VERSION ""

NS_ :

BS_:

BU_: VCU SOBEK_SDCxxxx RS_RPS BypassValve OilPump SOBEK_SDCxxxx WaterPump

BO_ 865 SOBEK_SetSpeed: 2 VCU
 SG_ SOBEK_SpeedCommand : 0|16@1+ (1,0) [0|0] "rpm"  SOBEK_SDCxxxx

BO_ 881 SOBEK_Status: 8 SOBEK_SDCxxxx
 SG_ SOBEK_TempFeedback : 32|16@1+ (0.1,0) [0|0] "100m°C"  VCU
 SG_ SOBEK_DCVoltageFeedback : 48|16@1+ (1,0) [0|0] "mV"  VCU
 SG_ SOBEK_SpeedFeedback : 0|16@1- (1,0) [0|0] "rpm"  VCU
 SG_ SOBEK_CurrentFeedback : 16|16@1- (1,0) [0|0] "100mA"  VCU

BO_ 897 SOBEK_Diagnostic_Message: 5 SOBEK_SDCxxxx
 SG_ Diagnostic_header M : 0|8@1+ (1,0) [16|16] ""  VCU
 SG_ Master_ID m1 : 8|16@1+ (1,0) [0|0] ""  VCU
 SG_ Status_ID m2 : 24|16@1+ (1,0) [0|0] ""  VCU
 SG_ Command_ID m2 : 8|16@1+ (1,0) [0|0] ""  VCU
 SG_ GWS_Status_ID m3 : 24|16@1+ (1,0) [0|0] ""  VCU
 SG_ GWS_Command_ID m3 : 8|16@1+ (1,0) [0|0] ""  VCU
 SG_ UNTERNUMMER_SOFTWARE m4 : 8|8@1+ (1,0) [0|0] ""  VCU
 SG_ HAUPTNUMMER_SOFTWARE m4 : 16|8@1+ (1,0) [0|0] ""  VCU
 SG_ ParameterVersion m5 : 8|16@1+ (1,0) [0|0] ""  VCU
 SG_ Betriebszaehler m6 : 8|32@1+ (1,0) [0|0] ""  VCU
 SG_ Encoder_Offset m7 : 8|16@1+ (1,0) [0|0] ""  VCU
 SG_ Side_MOSFETs m16 : 8|2@1+ (1,0) [0|0] ""  VCU
 SG_ Offset_of_EMF_measurement m16 : 10|1@1+ (1,0) [0|0] ""  VCU
 SG_ Offset_of_current_measurement m16 : 11|1@1+ (1,0) [0|0] ""  VCU
 SG_ Under_voltage_Selftest m16 : 12|1@1+ (1,0) [0|0] ""  VCU
 SG_ Over_voltage_Selftest m16 : 13|1@1+ (1,0) [0|0] ""  VCU
 SG_ Over_temperature_of_MOSFETs m16 : 14|1@1+ (1,0) [0|0] ""  VCU
 SG_ Disconnection_of_motor_cables m16 : 15|1@1+ (1,0) [0|0] ""  VCU
 SG_ No_parameter_data_in_EEPROM m16 : 16|1@1+ (1,0) [0|0] ""  VCU
 SG_ CRC_error_of_EEPROM m16 : 17|1@1+ (1,0) [0|0] ""  VCU
 SG_ Size_of_EEPROM m16 : 18|1@1+ (1,0) [0|0] ""  VCU
 SG_ Version_of_EEPROM m16 : 19|1@1+ (1,0) [0|0] ""  VCU
 SG_ Not_defined m16 : 20|1@1+ (1,0) [0|0] ""  VCU
 SG_ Not_defined m16 : 21|1@1+ (1,0) [0|0] ""  VCU
 SG_ Not_defined m16 : 22|1@1+ (1,0) [0|0] ""  VCU
 SG_ Not_defined m16 : 23|1@1+ (1,0) [0|0] ""  VCU
 SG_ Over_voltage_Operation m16 : 24|1@1+ (1,0) [0|0] ""  VCU
 SG_ Over_voltage m16 : 25|1@1+ (1,0) [0|0] ""  VCU
 SG_ Under_voltage_Operation m16 : 26|1@1+ (1,0) [0|0] ""  VCU
 SG_ Over_temperature m16 : 27|1@1+ (1,0) [0|0] ""  VCU
 SG_ Operation_system_watchdog m16 : 28|1@1+ (1,0) [0|0] ""  VCU
 SG_ Not_defined m16 : 29|1@1+ (1,0) [0|0] ""  VCU
 SG_ Not_defined m16 : 30|1@1+ (1,0) [0|0] ""  VCU

BO_ 260 Tool_RealTimeClock_Cmd: 6 VCU
 SG_ RPS_RTC_Second : 40|8@1- (1,0) [0|59] "" Vector__XXX
 SG_ RPS_RTC_Minute : 32|8@1- (1,0) [0|59] "" Vector__XXX
 SG_ RPS_RTC_Hour : 24|8@1- (1,0) [0|23] "" Vector__XXX
 SG_ RPS_RTC_Day : 16|8@1- (1,0) [0|31] "" Vector__XXX
 SG_ RPS_RTC_Month : 8|8@1- (1,0) [0|12] "" Vector__XXX
 SG_ RPS_RTC_Year : 0|8@1- (1,0) [0|255] "" Vector__XXX

BO_ 259 RPS_RealTimeClock_Data: 6 RS_RPS
 SG_ RPS_RTC_Second : 40|8@1- (1,0) [0|59] "" Vector__XXX
 SG_ RPS_RTC_Minute : 32|8@1- (1,0) [0|59] "" Vector__XXX
 SG_ RPS_RTC_Hour : 24|8@1- (1,0) [0|23] "" Vector__XXX
 SG_ RPS_RTC_Day : 16|8@1- (1,0) [0|31] "" Vector__XXX
 SG_ RPS_RTC_Month : 8|8@1- (1,0) [0|12] "" Vector__XXX
 SG_ RPS_RTC_Year : 0|8@1- (1,0) [0|255] "" Vector__XXX

BO_ 289 RPS_BMS_ASICStateInfo: 8 RS_RPS
 SG_ RPS_NBMSASICBalanceCond : 31|8@0+ (1,0) [0|255] "" Vector__XXX
 SG_ RPS_NBMSASICPowerOffCnt : 39|8@0+ (1,0) [0|255] "" Vector__XXX
 SG_ RPS_NBMSASICFirstResetType : 15|8@0+ (1,0) [0|255] "" Vector__XXX
 SG_ RPS_NBMSASICResetCount : 7|8@0+ (1,0) [0|255] "" Vector__XXX
 SG_ RPS_NBMSASICState : 23|8@0+ (1,0) [0|255] "" Vector__XXX
 SG_ RPS_NBMSASICBalanceMask : 55|16@0+ (1,0) [0|66535] "" Vector__XXX

BO_ 258 RPS_Programming_Command: 8 Vector__XXX

BO_ 257 RPS_Programming_Response: 8 Vector__XXX

BO_ 276 RPS_OutputStates4: 8 RS_RPS
 SG_ RPS_BBalancingActive : 20|1@0+ (1,0) [0|1] "" Vector__XXX
 SG_ RPS_BPackOverloadWarning : 19|1@0+ (1,0) [0|1] "" Vector__XXX
 SG_ RPS_VOutput : 39|8@0+ (0.08,0) [0|20.4] "V" Vector__XXX
 SG_ RPS_VBattery : 47|8@0+ (0.08,0) [0|20.4] "V" Vector__XXX
 SG_ RPS_NRPSLatestFault : 31|8@0+ (1,0) [0|255] "" Vector__XXX
 SG_ RPS_NBMSControlState : 23|3@0+ (1,0) [0|5] "" Vector__XXX
 SG_ RPS_IBattery : 55|16@0- (0.01,0) [-327.68|327.67] "A" Vector__XXX
 SG_ RPS_BPrimaryOutoutEnableState : 17|1@0+ (1,0) [0|1] "" Vector__XXX
 SG_ RPS_BPackHealthState : 18|1@0+ (1,0) [0|1] "" Vector__XXX
 SG_ RPS_BMasterEnableInputState : 16|1@0+ (1,0) [0|1] "" Vector__XXX
 SG_ RPS_IOutput26 : 15|8@0+ (0.01,0) [0|2.55] "A" Vector__XXX
 SG_ RPS_IOutput25 : 7|8@0+ (0.01,0) [0|2.55] "A" Vector__XXX

BO_ 275 RPS_OutputStates3: 8 RS_RPS
 SG_ RPS_IOutput24 : 63|8@0+ (0.01,0) [0|2.55] "A" Vector__XXX
 SG_ RPS_IOutput23 : 55|8@0+ (0.01,0) [0|2.55] "A" Vector__XXX
 SG_ RPS_IOutput22 : 47|8@0+ (0.01,0) [0|2.55] "A" Vector__XXX
 SG_ RPS_IOutput21 : 39|8@0+ (0.01,0) [0|2.55] "A" Vector__XXX
 SG_ RPS_IOutput20 : 31|8@0+ (0.01,0) [0|2.55] "A" Vector__XXX
 SG_ RPS_IOutput19 : 23|8@0+ (0.01,0) [0|2.55] "A" Vector__XXX
 SG_ RPS_IOutput18 : 15|8@0+ (0.01,0) [0|2.55] "A" Vector__XXX
 SG_ RPS_IOutput17 : 7|8@0+ (0.01,0) [0|2.55] "A" Vector__XXX

BO_ 274 RPS_OutputStates2: 8 RS_RPS
 SG_ RPS_IOutput9 : 7|8@0+ (0.04,0) [0|10.2] "A" Vector__XXX
 SG_ RPS_IOutput12 : 31|8@0+ (0.04,0) [0|10.2] "A" Vector__XXX
 SG_ RPS_IOutput16 : 63|8@0+ (0.04,0) [0|10.2] "A" Vector__XXX
 SG_ RPS_IOutput15 : 55|8@0+ (0.04,0) [0|10.2] "A" Vector__XXX
 SG_ RPS_IOutput14 : 47|8@0+ (0.04,0) [0|10.2] "A" Vector__XXX
 SG_ RPS_IOutput13 : 39|8@0+ (0.04,0) [0|10.2] "A" Vector__XXX
 SG_ RPS_IOutput11 : 23|8@0+ (0.04,0) [0|10.2] "A" Vector__XXX
 SG_ RPS_IOutput10 : 15|8@0+ (0.04,0) [0|10.2] "A" Vector__XXX

BO_ 273 RPS_OutputStates1: 8 RS_RPS
 SG_ RPS_IOutput8 : 63|8@0+ (0.08,0) [0|20.4] "A" Vector__XXX
 SG_ RPS_IOutput7 : 55|8@0+ (0.08,0) [0|20.4] "A" Vector__XXX
 SG_ RPS_IOutput6 : 47|8@0+ (0.08,0) [0|20.4] "A" Vector__XXX
 SG_ RPS_IOutput5 : 39|8@0+ (0.08,0) [0|20.4] "A" Vector__XXX
 SG_ RPS_IOutput4 : 31|8@0+ (0.08,0) [0|20.4] "A" Vector__XXX
 SG_ RPS_IOutput3 : 23|8@0+ (0.08,0) [0|20.4] "A" Vector__XXX
 SG_ RPS_IOutput2 : 15|8@0+ (0.08,0) [0|20.4] "A" Vector__XXX
 SG_ RPS_IOutput1 : 7|8@0+ (0.08,0) [0|20.4] "A" Vector__XXX

BO_ 272 RPS_OutputStates0: 8 RS_RPS
 SG_ RPS_BOutputResetState : 54|1@0+ (1,0) [0|1] "" Vector__XXX
 SG_ RPS_BIsolatorStateRequestFB : 53|1@0+ (1,0) [0|1] "" Vector__XXX
 SG_ RPS_BIsolatorOverrideActive : 52|1@0+ (1,0) [0|1] "" Vector__XXX
 SG_ RPS_NOutput9State : 17|2@0+ (1,0) [0|3] "" Vector__XXX
 SG_ RPS_NOutput8State : 15|2@0+ (1,0) [0|3] "" Vector__XXX
 SG_ RPS_NOutput7State : 13|2@0+ (1,0) [0|3] "" Vector__XXX
 SG_ RPS_NOutput6State : 11|2@0+ (1,0) [0|3] "" Vector__XXX
 SG_ RPS_NOutput5State : 9|2@0+ (1,0) [0|3] "" Vector__XXX
 SG_ RPS_NOutput4State : 7|2@0+ (1,0) [0|3] "" Vector__XXX
 SG_ RPS_NOutput3State : 5|2@0+ (1,0) [0|3] "" Vector__XXX
 SG_ RPS_NOutput2State : 3|2@0+ (1,0) [0|3] "" Vector__XXX
 SG_ RPS_NOutput26State : 51|2@0+ (1,0) [0|3] "" Vector__XXX
 SG_ RPS_NOutput25State : 49|2@0+ (1,0) [0|3] "" Vector__XXX
 SG_ RPS_NOutput24State : 47|2@0+ (1,0) [0|3] "" Vector__XXX
 SG_ RPS_NOutput23State : 45|2@0+ (1,0) [0|3] "" Vector__XXX
 SG_ RPS_NOutput22State : 43|2@0+ (1,0) [0|3] "" Vector__XXX
 SG_ RPS_NOutput21State : 41|2@0+ (1,0) [0|3] "" Vector__XXX
 SG_ RPS_NOutput20State : 39|2@0+ (1,0) [0|3] "" Vector__XXX
 SG_ RPS_NOutput1State : 1|2@0+ (1,0) [0|3] "" Vector__XXX
 SG_ RPS_NOutput19State : 37|2@0+ (1,0) [0|3] "" Vector__XXX
 SG_ RPS_NOutput18State : 35|2@0+ (1,0) [0|3] "" Vector__XXX
 SG_ RPS_NOutput17State : 33|2@0+ (1,0) [0|3] "" Vector__XXX
 SG_ RPS_NOutput16State : 31|2@0+ (1,0) [0|3] "" Vector__XXX
 SG_ RPS_NOutput15State : 29|2@0+ (1,0) [0|3] "" Vector__XXX
 SG_ RPS_NOutput14State : 27|2@0+ (1,0) [0|3] "" Vector__XXX
 SG_ RPS_NOutput13State : 25|2@0+ (1,0) [0|3] "" Vector__XXX
 SG_ RPS_NOutput12State : 23|2@0+ (1,0) [0|3] "" Vector__XXX
 SG_ RPS_NOutput11State : 21|2@0+ (1,0) [0|3] "" Vector__XXX
 SG_ RPS_NOutput10State : 19|2@0+ (1,0) [0|3] "" Vector__XXX

BO_ 256 RPS_OutputCommand: 8 VCU
 SG_ RPS_BIsolatorOverrideStateDem : 28|1@0+ (1,0) [0|0] "" Vector__XXX
 SG_ RPS_BIsolatorOverrideEnableDem : 27|1@0+ (1,0) [0|0] "" Vector__XXX
 SG_ RPS_BOutput23EnableDem : 22|1@0+ (1,0) [0|0] "" Vector__XXX
 SG_ RPS_BOutputResetDem : 26|1@0+ (1,0) [0|0] "" Vector__XXX
 SG_ RPS_BOutput9EnableDem : 8|1@0+ (1,0) [0|0] "" Vector__XXX
 SG_ RPS_BOutput8EnableDem : 7|1@0+ (1,0) [0|0] "" Vector__XXX
 SG_ RPS_BOutput7EnableDem : 6|1@0+ (1,0) [0|0] "" Vector__XXX
 SG_ RPS_BOutput6EnableDem : 5|1@0+ (1,0) [0|0] "" Vector__XXX
 SG_ RPS_BOutput5EnableDem : 4|1@0+ (1,0) [0|0] "" Vector__XXX
 SG_ RPS_BOutput4EnableDem : 3|1@0+ (1,0) [0|0] "" Vector__XXX
 SG_ RPS_BOutput3EnableDem : 2|1@0+ (1,0) [0|0] "" Vector__XXX
 SG_ RPS_BOutput2EnableDem : 1|1@0+ (1,0) [0|0] "" Vector__XXX
 SG_ RPS_BOutput26EnableDem : 25|1@0+ (1,0) [0|0] "" Vector__XXX
 SG_ RPS_BOutput25EnableDem : 24|1@0+ (1,0) [0|0] "" Vector__XXX
 SG_ RPS_BOutput24EnableDem : 23|1@0+ (1,0) [0|0] "" Vector__XXX
 SG_ RPS_BOutput22EnableDem : 21|1@0+ (1,0) [0|0] "" Vector__XXX
 SG_ RPS_BOutput21EnableDem : 20|1@0+ (1,0) [0|0] "" Vector__XXX
 SG_ RPS_BOutput20EnableDem : 19|1@0+ (1,0) [0|0] "" Vector__XXX
 SG_ RPS_BOutput1EnableDem : 0|1@0+ (1,0) [0|0] "" Vector__XXX
 SG_ RPS_BOutput19EnableDem : 18|1@0+ (1,0) [0|0] "" Vector__XXX
 SG_ RPS_BOutput18EnableDem : 17|1@0+ (1,0) [0|0] "" Vector__XXX
 SG_ RPS_BOutput17EnableDem : 16|1@0+ (1,0) [0|0] "" Vector__XXX
 SG_ RPS_BOutput16EnableDem : 15|1@0+ (1,0) [0|0] "" Vector__XXX
 SG_ RPS_BOutput15EnableDem : 14|1@0+ (1,0) [0|0] "" Vector__XXX
 SG_ RPS_BOutput14EnableDem : 13|1@0+ (1,0) [0|0] "" Vector__XXX
 SG_ RPS_BOutput13EnableDem : 12|1@0+ (1,0) [0|0] "" Vector__XXX
 SG_ RPS_BOutput12EnableDem : 11|1@0+ (1,0) [0|0] "" Vector__XXX
 SG_ RPS_BOutput11EnableDem : 10|1@0+ (1,0) [0|0] "" Vector__XXX
 SG_ RPS_BOutput10EnableDem : 9|1@0+ (1,0) [0|0] "" Vector__XXX

BO_ 305 RPS_Rotations: 8 RS_RPS
 SG_ RPS_nRotationZ : 39|16@0- (0.01,0) [-500|500] "°/s" Vector__XXX
 SG_ RPS_nRotationY : 23|16@0- (0.01,0) [-500|500] "°/s" Vector__XXX
 SG_ RPS_nRotationX : 7|16@0- (0.01,0) [-500|500] "°/s" Vector__XXX

BO_ 304 RPS_Accels: 8 RS_RPS
 SG_ RPS_gAccelZ : 39|16@0- (0.001,0) [-16|16] "g" Vector__XXX
 SG_ RPS_gAccelY : 23|16@0- (0.001,0) [-16|16] "g" Vector__XXX
 SG_ RPS_gAccelX : 7|16@0- (0.001,0) [-16|16] "g" Vector__XXX

BO_ 288 RPS_VersionInfo: 8 RS_RPS
 SG_ RPS_HWVersion_DMinor : 31|8@0+ (1,0) [0|255] "" Vector__XXX
 SG_ RPS_HWVersion_DMajor : 23|8@0+ (1,0) [0|255] "" Vector__XXX
 SG_ RPS_SWVersionIDMinor : 15|8@0+ (1,0) [0|255] "" Vector__XXX
 SG_ RPS_SWVersionIDMajor : 7|8@0+ (1,0) [0|255] "" Vector__XXX

BO_ 278 RPS_BatteryTemps: 8 RS_RPS
 SG_ RPS_TPack3 : 23|8@0+ (0.5,-20) [-20|105] "degC" Vector__XXX
 SG_ RPS_TPack2 : 15|8@0+ (0.5,-20) [-20|105] "degC" Vector__XXX
 SG_ RPS_TPack1 : 7|8@0+ (0.5,-20) [-20|105] "degC" Vector__XXX

BO_ 277 RPS_BatteryVoltages: 8 RS_RPS
 SG_ RPS_VCellStack4 : 55|16@0+ (0.0001,0) [0|6] "V" Vector__XXX
 SG_ RPS_VCellStack3 : 39|16@0+ (0.0001,0) [0|6] "V" Vector__XXX
 SG_ RPS_VCellStack2 : 23|16@0+ (0.0001,0) [0|6] "V" Vector__XXX
 SG_ RPS_VCellStack1 : 7|16@0+ (0.0001,0) [0|6] "V" Vector__XXX

BO_ 869 CommandMsg: 2 VCU
 SG_ PositionRef : 0|16@1+ (0.1,0) [0|1000] "%" Vector__XXX

BO_ 885 StatusMsg: 2 BypassValve
 SG_ Position : 0|16@1+ (0.1,0) [0|1000] "%" Vector__XXX

BO_ 837 DiagnosticMsg: 5 BypassValve
 SG_ DeviceID3 m9 : 8|32@1+ (1,0) [0|4294967295] "" Vector__XXX
 SG_ DeviceID2 m8 : 8|32@1+ (1,0) [0|4294967295] "" Vector__XXX
 SG_ DeviceID1 m7 : 8|32@1+ (1,0) [0|4294967295] "" Vector__XXX
 SG_ CommandID m3 : 8|16@1+ (1,0) [0|65535] "" Vector__XXX
 SG_ BootloaderVersion m6 : 8|16@1+ (1,0) [0|65535] "" Vector__XXX
 SG_ BootloaderUpdateCounter m6 : 24|16@1+ (1,0) [0|65535] "" Vector__XXX
 SG_ OperationError m16 : 8|16@1+ (1,0) [0|65535] "" Vector__XXX
 SG_ SelfcheckStatus m1 : 8|16@1+ (1,0) [0|65535] "" Vector__XXX
 SG_ DiagnosticHeader M : 0|8@1+ (1,0) [0|255] "" Vector__XXX
 SG_ MasterID m2 : 8|16@1+ (1,0) [0|65535] "" Vector__XXX
 SG_ StatusID m3 : 24|16@1+ (1,0) [0|0] "" Vector__XXX
 SG_ FirmwareVersion m4 : 8|16@1+ (1,0) [0|0] "" Vector__XXX
 SG_ ParameterVersion m4 : 24|16@1+ (1,0) [0|65535] "" Vector__XXX
 SG_ OperationCounter m5 : 8|32@1+ (1,0) [0|4294967295] "s" Vector__XXX

BO_ 1376 SOBEK_Master: 8 Vector__XXX

BO_ 1377 SOBEK_Command: 2 VCU
 SG_ Target_Speed : 0|16@1- (1,0) [-32768|32767] "rpm"  SOBEK_SDCxxxx

BO_ 1378 SOBEK_Status: 8 OilPump
 SG_ ESC_Temperature : 32|16@1+ (0.1,0) [0|200] "Celsius" Vector__XXX
 SG_ DC_Voltage : 48|16@1+ (0.001,0) [0|65.535] "V" Vector__XXX
 SG_ Motor_Speed : 0|16@1- (1,0) [-32768|32767] "rpm" Vector__XXX
 SG_ Motor_Current : 16|16@1+ (0.1,0) [0|6553.5] "A" Vector__XXX

BO_ 1379 SOBEK_Diagnostic: 5 OilPump
 SG_ HW_ID3 m9 : 8|32@1+ (1,0) [0|4294967295] "" Vector__XXX
 SG_ HW_ID2 m8 : 8|32@1+ (1,0) [0|4294967295] "" Vector__XXX
 SG_ HW_ID1 m7 : 8|32@1+ (1,0) [0|4294967295] "" Vector__XXX
 SG_ Operation_Warning m16 : 16|8@1+ (1,0) [0|255] "" Vector__XXX
 SG_ Bootloader_Version m6 : 8|16@1+ (1,0) [0|65535] "" Vector__XXX
 SG_ Bootloader_Update_Counter m6 : 24|16@1+ (1,0) [0|65535] "" Vector__XXX
 SG_ Operation_Error m16 : 8|8@1+ (1,0) [0|255] "" Vector__XXX
 SG_ Parameter_Version m4 : 24|16@1+ (1,0) [0|65535] "" Vector__XXX
 SG_ Self_Test m1 : 8|16@1+ (1,0) [0|65535] "" Vector__XXX
 SG_ Diagnostic_Header M : 0|8@1+ (1,0) [0|255] "" Vector__XXX
 SG_ Master_ID m2 : 8|11@1+ (1,0) [0|2047] "" Vector__XXX
 SG_ Status_ID m3 : 24|11@1+ (1,0) [0|2047] "" Vector__XXX
 SG_ Command_ID m3 : 8|11@1+ (1,0) [0|2047] "" Vector__XXX
 SG_ Software_Version m4 : 8|16@1+ (1,0) [0|65535] "" Vector__XXX
 SG_ Operation_Counter m5 : 8|32@1+ (1,0) [0|4294967295] "s" Vector__XXX

BO_ 1360 SOBEK_Master: 8 Vector__XXX

BO_ 1361 SOBEK_Command: 2 VCU
 SG_ Target_Speed : 0|16@1- (1,0) [-32768|32767] "rpm" Vector__XXX

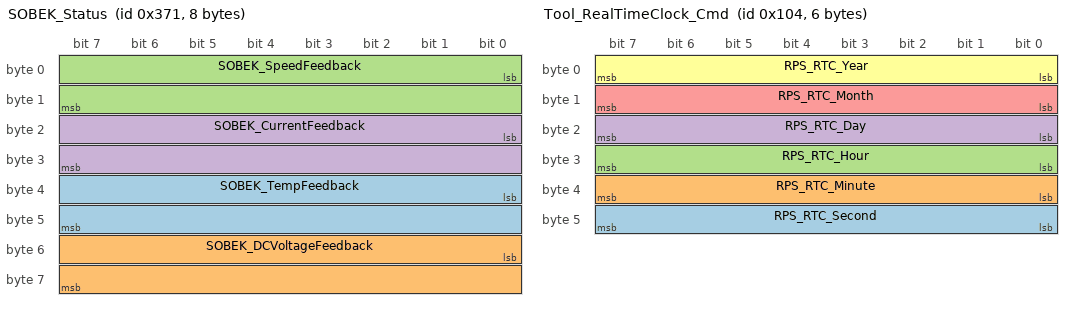
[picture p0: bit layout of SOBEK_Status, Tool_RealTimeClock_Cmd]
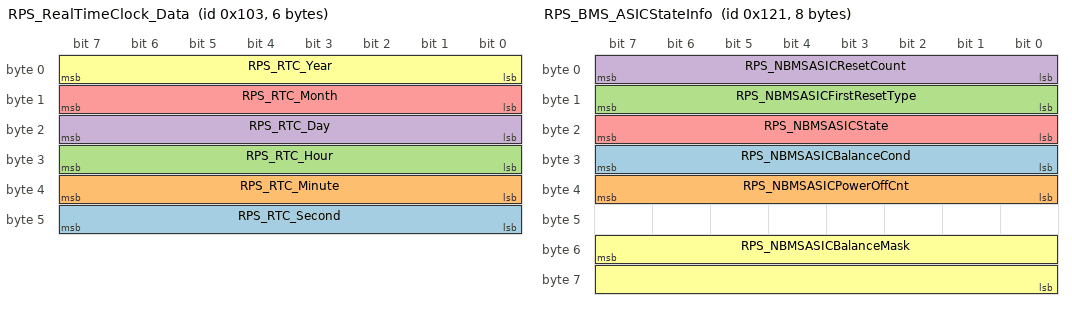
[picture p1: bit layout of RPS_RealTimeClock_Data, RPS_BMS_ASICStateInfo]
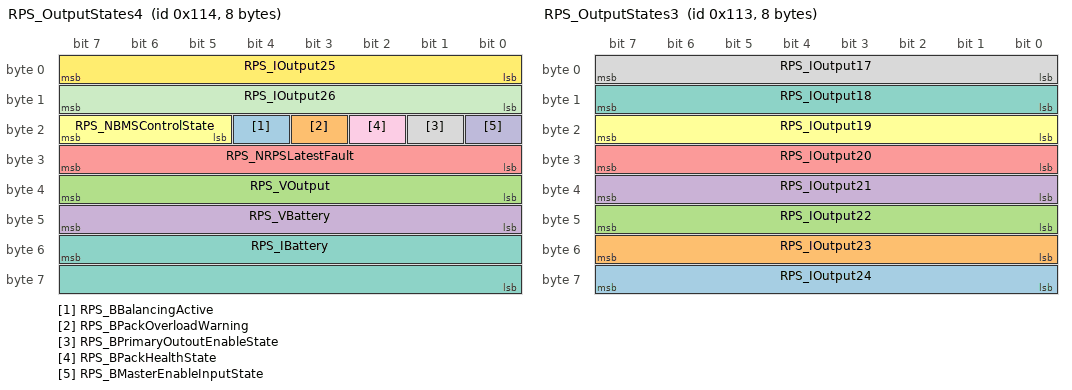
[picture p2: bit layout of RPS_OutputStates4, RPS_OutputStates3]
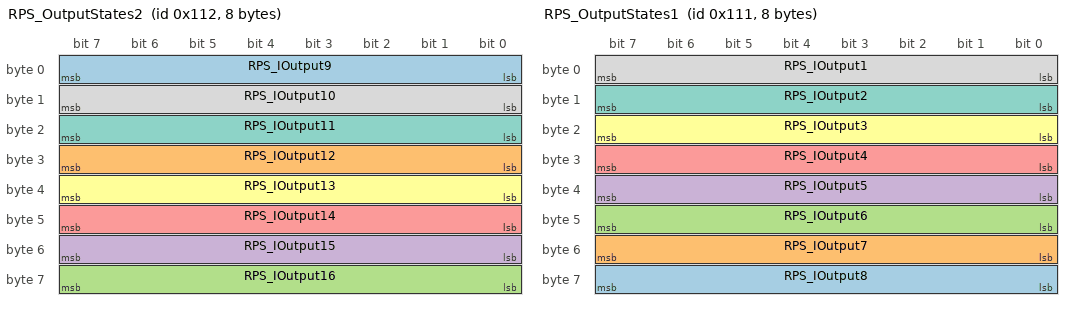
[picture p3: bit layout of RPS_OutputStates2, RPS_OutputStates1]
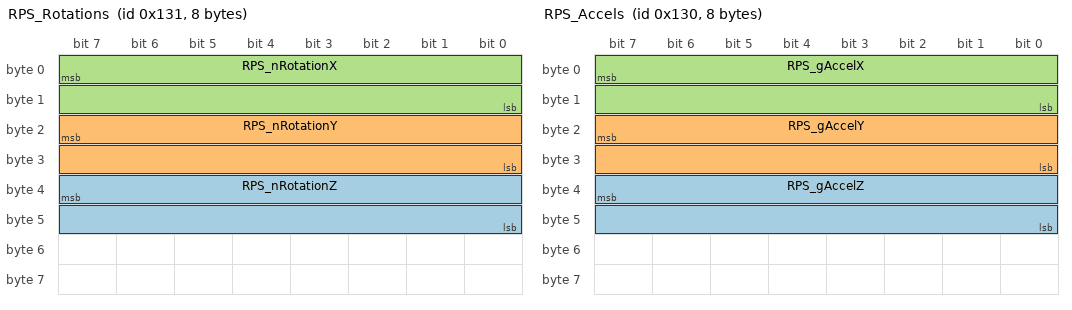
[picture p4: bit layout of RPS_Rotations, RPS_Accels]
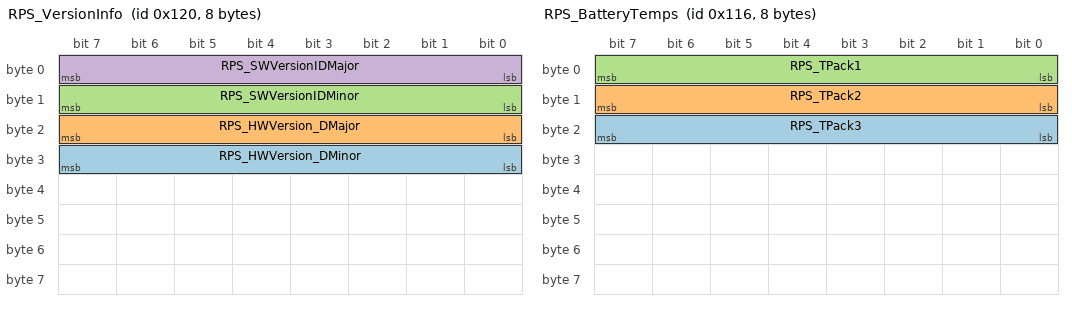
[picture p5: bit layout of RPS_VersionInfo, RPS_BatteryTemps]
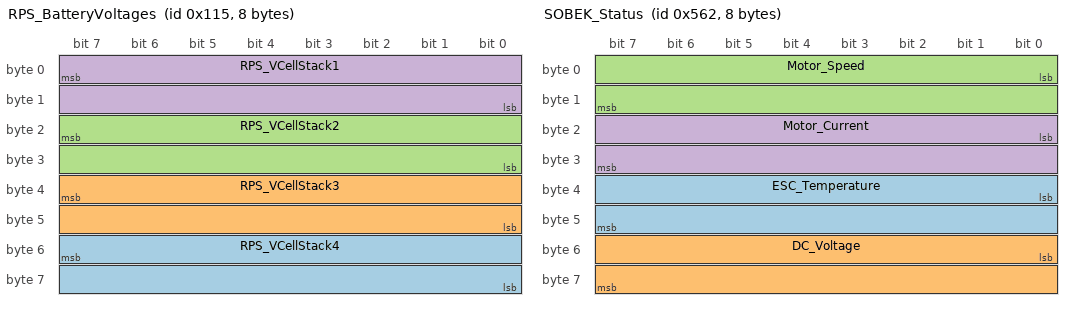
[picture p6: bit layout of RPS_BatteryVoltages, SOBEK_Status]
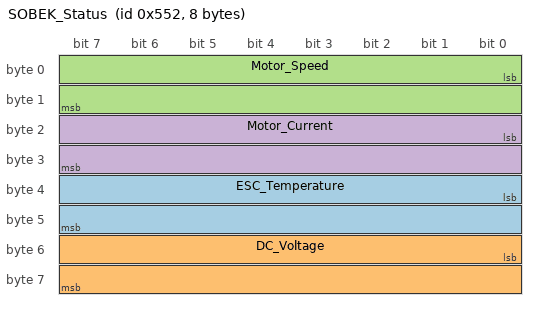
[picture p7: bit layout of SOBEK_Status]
BO_ 1362 SOBEK_Status: 8 WaterPump
 SG_ ESC_Temperature : 32|16@1+ (0.1,0) [0|200] "Celsius" Vector__XXX
 SG_ DC_Voltage : 48|16@1+ (0.001,0) [0|65.535] "V" Vector__XXX
 SG_ Motor_Speed : 0|16@1- (1,0) [-32768|32767] "rpm" Vector__XXX
 SG_ Motor_Current : 16|16@1+ (0.1,0) [0|6553.5] "A" Vector__XXX

BO_ 1363 SOBEK_Diagnostic: 5 WaterPump
 SG_ HW_ID3 m9 : 8|32@1+ (1,0) [0|4294967295] "" Vector__XXX
 SG_ HW_ID2 m8 : 8|32@1+ (1,0) [0|4294967295] "" Vector__XXX
 SG_ HW_ID1 m7 : 8|32@1+ (1,0) [0|4294967295] "" Vector__XXX
 SG_ Operation_Warning m16 : 16|8@1+ (1,0) [0|255] "" Vector__XXX
 SG_ Bootloader_Version m6 : 8|16@1+ (1,0) [0|65535] "" Vector__XXX
 SG_ Bootloader_Update_Counter m6 : 24|16@1+ (1,0) [0|65535] "" Vector__XXX
 SG_ Operation_Error m16 : 8|8@1+ (1,0) [0|255] "" Vector__XXX
 SG_ Parameter_Version m4 : 24|16@1+ (1,0) [0|65535] "" Vector__XXX
 SG_ Self_Test m1 : 8|16@1+ (1,0) [0|65535] "" Vector__XXX
 SG_ Diagnostic_Header M : 0|8@1+ (1,0) [0|255] "" Vector__XXX
 SG_ Master_ID m2 : 8|11@1+ (1,0) [0|2047] "" Vector__XXX
 SG_ Status_ID m3 : 24|11@1+ (1,0) [0|2047] "" Vector__XXX
 SG_ Command_ID m3 : 8|11@1+ (1,0) [0|2047] "" Vector__XXX
 SG_ Software_Version m4 : 8|16@1+ (1,0) [0|65535] "" Vector__XXX
 SG_ Operation_Counter m5 : 8|32@1+ (1,0) [0|4294967295] "s" Vector__XXX

CM_ "bit/s";
CM_ BO_ 260 "Send by a CAN Tool to set current date/time
Cycle time: on demand
Please assign message ID";
CM_ BO_ 259 "Send by RPS received by RVI. 
Cycle time 1s (periodic)
Please assign message ID";
CM_ SG_ 289 RPS_NBMSASICBalanceCond "ASIC state conditions leading to a balancing command (before a balancing command)";
CM_ SG_ 289 RPS_NBMSASICPowerOffCnt "When not balancing BMS ASIC triggers sequence of SPI communication leading to a capture of new measurements";
CM_ SG_ 289 RPS_NBMSASICFirstResetType "Only a cause of a first erroneous BMS ASIC reset is stored
";
CM_ SG_ 289 RPS_NBMSASICResetCount "Count saturated at 255";
CM_ SG_ 289 RPS_NBMSASICState "Each value indicates an ongoing phase of balancing related BMS ASIC SPI communication ";
CM_ SG_ 289 RPS_NBMSASICBalanceMask "Bits corresponding to balancing conditions evaluated as TRUE are set to 1";
CM_ SG_ 276 RPS_BBalancingActive "Control command state for main battery contactor";
CM_ SG_ 276 RPS_BPackOverloadWarning "Control command state for main battery contactor";
CM_ SG_ 276 RPS_VOutput "BMS measured pack total output voltage";
CM_ SG_ 276 RPS_VBattery "BMS measured pack total output voltage";
CM_ SG_ 276 RPS_NRPSLatestFault "Control state of BMS control function
";
CM_ SG_ 276 RPS_NBMSControlState "Control state of BMS control function
";
CM_ SG_ 276 RPS_IBattery "Measured battery pack current.";
CM_ SG_ 276 RPS_BPrimaryOutoutEnableState "State of main enable input pin (Low=TurnOn, High=TurnOff)";
CM_ SG_ 276 RPS_BPackHealthState "State of main enable input pin (Low=TurnOn, High=TurnOff)";
CM_ SG_ 276 RPS_BMasterEnableInputState "State of main enable input pin (Low=TurnOn, High=TurnOff)";
CM_ SG_ 276 RPS_IOutput26 "Measured battery pack current.";
CM_ SG_ 276 RPS_IOutput25 "Measured battery pack current.";
CM_ SG_ 275 RPS_IOutput24 "Measured battery pack current.";
CM_ SG_ 275 RPS_IOutput23 "Measured battery pack current.";
CM_ SG_ 275 RPS_IOutput22 "Measured battery pack current.";
CM_ SG_ 275 RPS_IOutput21 "Measured battery pack current.";
CM_ SG_ 275 RPS_IOutput20 "Measured battery pack current.";
CM_ SG_ 275 RPS_IOutput19 "Measured battery pack current.";
CM_ SG_ 275 RPS_IOutput18 "Measured battery pack current.";
CM_ SG_ 275 RPS_IOutput17 "Measured battery pack current.";
CM_ SG_ 274 RPS_IOutput9 "Measured battery pack current.";
CM_ SG_ 274 RPS_IOutput12 "Measured battery pack current.";
CM_ SG_ 274 RPS_IOutput16 "Measured battery pack current.";
CM_ SG_ 274 RPS_IOutput15 "Measured battery pack current.";
CM_ SG_ 274 RPS_IOutput14 "Measured battery pack current.";
CM_ SG_ 274 RPS_IOutput13 "Measured battery pack current.";
CM_ SG_ 274 RPS_IOutput11 "Measured battery pack current.";
CM_ SG_ 274 RPS_IOutput10 "Measured battery pack current.";
CM_ SG_ 273 RPS_IOutput8 "Measured battery pack current.";
CM_ SG_ 273 RPS_IOutput7 "Measured battery pack current.";
CM_ SG_ 273 RPS_IOutput6 "Measured battery pack current.";
CM_ SG_ 273 RPS_IOutput5 "Measured battery pack current.";
CM_ SG_ 273 RPS_IOutput4 "Measured battery pack current.";
CM_ SG_ 273 RPS_IOutput3 "Measured battery pack current.";
CM_ SG_ 273 RPS_IOutput2 "Measured battery pack current.";
CM_ SG_ 273 RPS_IOutput1 "Measured battery pack current.";
CM_ SG_ 272 RPS_BIsolatorStateRequestFB "Control command state for main battery contactor";
CM_ SG_ 278 RPS_TPack3 "Cell measured temperature #3
";
CM_ SG_ 278 RPS_TPack2 "Cell measured temperature #2";
CM_ SG_ 278 RPS_TPack1 "Cell measured temperature #1";
CM_ SG_ 277 RPS_VCellStack4 "Cell module #1 measured voltage (top in series)";
CM_ SG_ 277 RPS_VCellStack3 "Cell module #1 measured voltage (upper middle in series)";
CM_ SG_ 277 RPS_VCellStack2 "Cell module #1 measured voltage (lower middle in series)";
CM_ SG_ 277 RPS_VCellStack1 "Cell module #1 measured voltage (lowest in series)";
CM_ BO_ 1376 "The SOBEK_Master message is only activated when a SOBEK bootloader or SOBEK software configuration tool is connected.";
CM_ BO_ 1379 "triggered: at initialization and only on occurrence.
periodic: at initialization and periodic.
periodic&triggered: at initialization, periodic and on occurrence.
deactivated: no diagnostic messages will be sent.";
CM_ BO_ 1360 "The SOBEK_Master message is only activated when a SOBEK bootloader or SOBEK software configuration tool is connected.";
CM_ BO_ 1363 "triggered: at initialization and only on occurrence.
periodic: at initialization and periodic.
periodic&triggered: at initialization, periodic and on occurrence.
deactivated: no diagnostic messages will be sent.";
BA_DEF_  "Baudrate" INT 0 1000000;
BA_DEF_ BO_  "GenMsgSendType" ENUM  "Cyclic","NotUsed","NotUsed","NotUsed","NotUsed","NotUsed","NotUsed","IfActive","NoMsgSendType","NotUsed";
BA_DEF_ BO_  "GenMsgCycleTime" INT 50 2000;
BA_DEF_ BO_  "GenMsgILSupport" ENUM  "No","Yes";
BA_DEF_ BU_  "ILUsed" ENUM  "No","Yes";
BA_DEF_DEF_  "Baudrate" 1000000;
BA_DEF_DEF_  "GenMsgSendType" "Cyclic";
BA_DEF_DEF_  "GenMsgCycleTime" 50;
BA_DEF_DEF_  "GenMsgILSupport" "Yes";
BA_DEF_DEF_  "ILUsed" "Yes";
BA_ "Baudrate" 1000;
BA_ "GenMsgCycleTime" BO_ 865 100;
BA_ "GenMsgCycleTime" BO_ 881 100;
